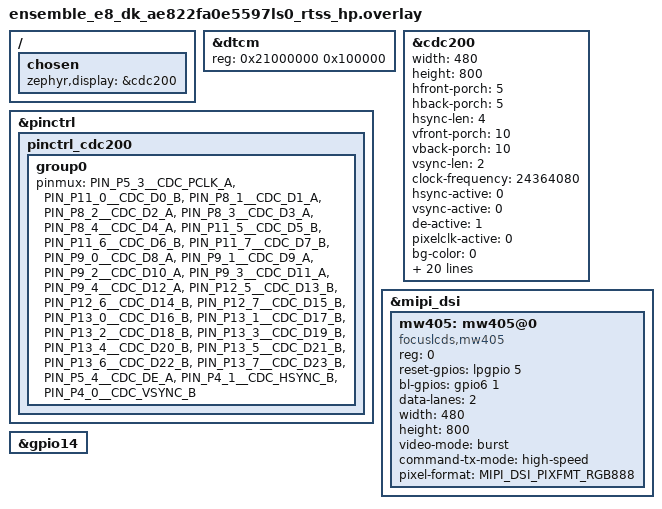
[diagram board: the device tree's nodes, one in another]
/* Copyright (C) 2026 Alif Semiconductor - All Rights Reserved.
 * Use, distribution and modification of this code is permitted under the
 * terms stated in the Alif Semiconductor Software License Agreement
 *
 * You should have received a copy of the Alif Semiconductor Software
 * License Agreement with this file. If not, please write to:
 * contact@alifsemi.com, or visit: https://alifsemi.com/license
 *
 */

//#include <dt-bindings/misc/alif_aipm_common.h>
#include <zephyr/dt-bindings/mipi_dsi/mipi_dsi.h>

/ {
	chosen {
		zephyr,display = &cdc200;
	};
};

/* Correct DTCM address to not sit over HEXSPI0 memory mirror */
&dtcm {
	reg = <0x21000000 0x100000>;
};

&cdc200 {
	width = <480>;
	height = <800>;
	hfront-porch = <5>;
	hback-porch = <5>;
	hsync-len = <4>;
	vfront-porch = <10>;
	vback-porch = <10>;
	vsync-len = <2>;
	clock-frequency = <24364080>;
	hsync-active = <0>;
	vsync-active = <0>;
	de-active = <1>;
	pixelclk-active = <0>;
	bg-color = <0>;
	enable-l1 = <1>;
	pixel-fmt-l1 = "rgb-888";
	def-back-color-l1 = <0>;
	win-x0-l1 = <0>;
	win-y0-l1 = <0>;
	win-x1-l1 = <480>;
	win-y1-l1 = <800>;
	blend-factor1-l1 = <4>;
	blend-factor2-l1 = <5>;
	const-alpha-l1 = <0xff>;
	enable-l2 = <0>;
	pixel-fmt-l2 = "undefined";
	win-x0-l2 = <0>;
	win-y0-l2 = <0>;
	win-x1-l2 = <0>;
	win-y1-l2 = <0>;
	blend-factor1-l2 = <6>;
	blend-factor2-l2 = <7>;
	const-alpha-l2 = <0xff>;
	pinctrl-0 = <&pinctrl_cdc200>;
	pinctrl-names = "default";
	status = "okay";
};

&pinctrl {
	pinctrl_cdc200: pinctrl_cdc200 {
		group0 {
			pinmux = <PIN_P5_3__CDC_PCLK_A>,
				 <PIN_P11_0__CDC_D0_B>,
				 <PIN_P8_1__CDC_D1_A>,
				 <PIN_P8_2__CDC_D2_A>,
				 <PIN_P8_3__CDC_D3_A>,
				 <PIN_P8_4__CDC_D4_A>,
				 <PIN_P11_5__CDC_D5_B>,
				 <PIN_P11_6__CDC_D6_B>,
				 <PIN_P11_7__CDC_D7_B>,
				 <PIN_P9_0__CDC_D8_A>,
				 <PIN_P9_1__CDC_D9_A>,
				 <PIN_P9_2__CDC_D10_A>,
				 <PIN_P9_3__CDC_D11_A>,
				 <PIN_P9_4__CDC_D12_A>,
				 <PIN_P12_5__CDC_D13_B>,
				 <PIN_P12_6__CDC_D14_B>,
				 <PIN_P12_7__CDC_D15_B>,
				 <PIN_P13_0__CDC_D16_B>,
				 <PIN_P13_1__CDC_D17_B>,
				 <PIN_P13_2__CDC_D18_B>,
				 <PIN_P13_3__CDC_D19_B>,
				 <PIN_P13_4__CDC_D20_B>,
				 <PIN_P13_5__CDC_D21_B>,
				 <PIN_P13_6__CDC_D22_B>,
				 <PIN_P13_7__CDC_D23_B>,
				 <PIN_P5_4__CDC_DE_A>,
				 <PIN_P4_1__CDC_HSYNC_B>,
				 <PIN_P4_0__CDC_VSYNC_B>;
		};
	};
};

&mipi_dsi {
	status = "okay";
	mw405: mw405@0 {
		status = "okay";
		compatible = "focuslcds,mw405";
		reg = <0>;
		reset-gpios = <&lpgpio 5 GPIO_ACTIVE_HIGH>;
		bl-gpios = <&gpio6 1 GPIO_ACTIVE_HIGH>;
		data-lanes = <2>;
		width = <480>;
		height = <800>;
		video-mode = "burst";
		command-tx-mode = "high-speed";
		pixel-format = <MIPI_DSI_PIXFMT_RGB888>;
	};
};

&gpio14 {
	status = "okay";
};

// TODO: we need to power these PHYS
/*
&aipm_run_default {
	phy-pwr-gating = <(ALIF_PHY_GATE_LDO_MASK |
			ALIF_PHY_GATE_MIPI_TX_DPHY_MASK |
			ALIF_PHY_GATE_MIPI_RX_DPHY_MASK |
			ALIF_PHY_GATE_MIPI_PLL_DPHY_MASK)>;
	ip-clock-gating = <(ALIF_IP_CLK_GATE_CDC200_MASK |
			ALIF_IP_CLK_GATE_MIPI_DSI_MASK |
			ALIF_IP_CLK_GATE_GPU_MASK)>;
};
*/
